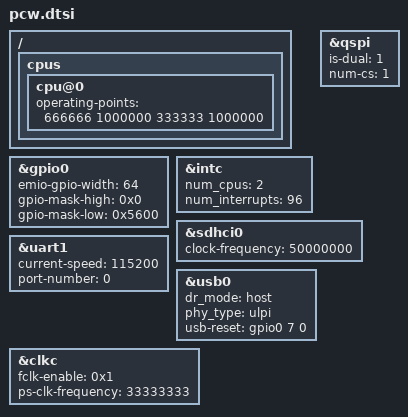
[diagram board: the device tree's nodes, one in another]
/*
 * CAUTION: This file is automatically generated by Xilinx.
 * Version: HSI 
 * Today is: Tue Feb  2 18:24:20 2016
*/


/ {
	cpus {
		cpu@0 {
			operating-points = <666666 1000000 333333 1000000>;
		};
	};
};
&gpio0 {
	emio-gpio-width = <64>;
	gpio-mask-high = <0x0>;
	gpio-mask-low = <0x5600>;
};
&intc {
	num_cpus = <2>;
	num_interrupts = <96>;
};
&qspi {
	is-dual = <1>;
	num-cs = <1>;
	status = "okay";
};
&sdhci0 {
	clock-frequency = <50000000>;
	status = "okay";
};
&uart1 {
	current-speed = <115200>;
	device_type = "serial";
	port-number = <0>;
	status = "okay";
};
&usb0 {
	dr_mode = "host";
	phy_type = "ulpi";
	status = "okay";
	usb-reset = <&gpio0 7 0>;
};
&clkc {
	fclk-enable = <0x1>;
	ps-clk-frequency = <33333333>;
};
